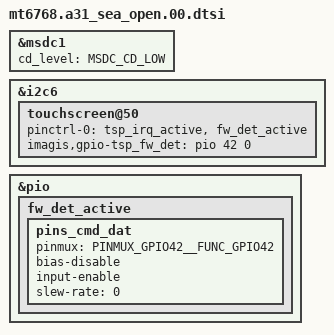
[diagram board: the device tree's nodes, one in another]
/* 
 * Generated by Samsung 
 * If these files should be changed, then please make a sync with MTK
*/

#include "../../mediatek/k68v1_64_titan/gpio02_a31_sea.dtsi"
#include "mt6768-a31_common.dtsi"
#include "mt6768-a31_camera_01.dtsi"
#include "mt6768-a31_sensor_grip_01.dtsi"
#include "s2mu106_motor.dtsi"
#include "mt6768-a31_input_common.dtsi"
#include "mt6768-a31_pm_common.dtsi"
#include "mt6768-a31_audio_common.dtsi"

/* Add Samsung configuration over here */

&msdc1 {
	cd_level = /bits/ 8 <MSDC_CD_LOW>;
};

&i2c6 {
	touchscreen@50 {
		pinctrl-0 = <&tsp_irq_active &fw_det_active>;
		imagis,gpio-tsp_fw_det = <&pio 42 0>;
	};
};

&pio {
	fw_det_active: fw_det_active {
		pins_cmd_dat {
			pinmux = <PINMUX_GPIO42__FUNC_GPIO42>;
			bias-disable;
			input-enable;
			slew-rate = <0>;
		};
	};
};

/*End of this file, DO NOT ADD ANYTHING HERE*/
